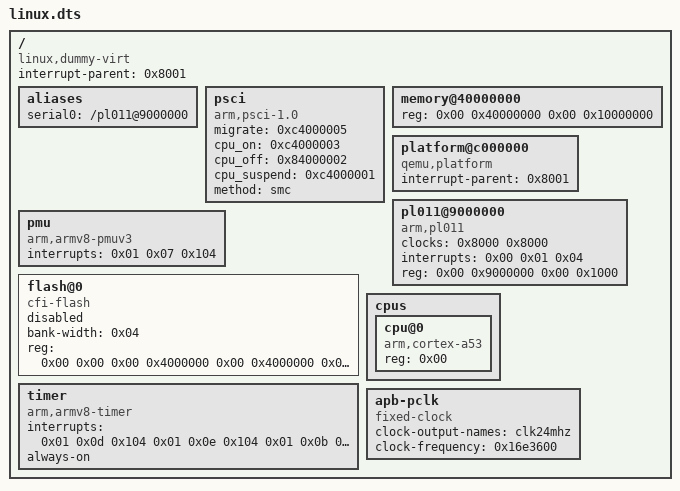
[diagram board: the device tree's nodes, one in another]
/dts-v1/;

/ {
	interrupt-parent = <0x8001>;
	#size-cells = <0x02>;
	#address-cells = <0x02>;
	compatible = "linux,dummy-virt";

	aliases {
		serial0 = "/pl011@9000000";
	};

	psci {
		migrate = <0xc4000005>;
		cpu_on = <0xc4000003>;
		cpu_off = <0x84000002>;
		cpu_suspend = <0xc4000001>;
		method = "smc";
		compatible = "arm,psci-1.0", "arm,psci-0.2", "arm,psci";
	};

	memory@40000000 {
		reg = <0x00 0x40000000 0x00 0x10000000>;
		device_type = "memory";
	};

	platform@c000000 {
		interrupt-parent = <0x8001>;
		ranges = <0x00 0x00 0xc000000 0x2000000>;
		#address-cells = <0x01>;
		#size-cells = <0x01>;
		compatible = "qemu,platform", "simple-bus";
	};

	pl011@9000000 {
		clock-names = "uartclk", "apb_pclk";
		clocks = <0x8000 0x8000>;
		interrupts = <0x00 0x01 0x04>;
		reg = <0x00 0x9000000 0x00 0x1000>;
		compatible = "arm,pl011", "arm,primecell";
	};

	pmu {
		interrupts = <0x01 0x07 0x104>;
		compatible = "arm,armv8-pmuv3";
	};

	flash@0 {
		bank-width = <0x04>;
		reg = <0x00 0x00 0x00 0x4000000 0x00 0x4000000 0x00 0x4000000>;
		compatible = "cfi-flash";
		status = "disabled";
	};

	cpus {
		#size-cells = <0x00>;
		#address-cells = <0x01>;

		cpu@0 {
			reg = <0x00>;
			compatible = "arm,cortex-a53";
			device_type = "cpu";
		};
	};

	timer {
		interrupts = <0x01 0x0d 0x104 0x01 0x0e 0x104 0x01 0x0b 0x104 0x01 0x0a 0x104>;
		always-on;
		compatible = "arm,armv8-timer", "arm,armv7-timer";
	};

	apb-pclk {
		phandle = <0x8000>;
		clock-output-names = "clk24mhz";
		clock-frequency = <0x16e3600>;
		#clock-cells = <0x00>;
		compatible = "fixed-clock";
	};
};
